# CW32L031 register map
Vendor: Wuhan Xinyuan Semiconductor Co.,Ltd; Series: CW32L03xx; File version: 1.2
CPU: CM0+ r0p1, little endian, no MPU, no FPU, 3 interrupt priority bits
Registers are 32-bit, read-write, no defined reset value unless marked. A register's access mark holds for its fields unless they carry their own. Offsets are from the block's base; [hi:lo] are bit positions; {n}, {i} and the like mark numbered series; 'fields as' and 'values as' point back to an identical list.

## ATIM
Base 0x40012C00
0x00 ARR
  [15:0] ARR
0x04 CNT
  [15:0] CNT
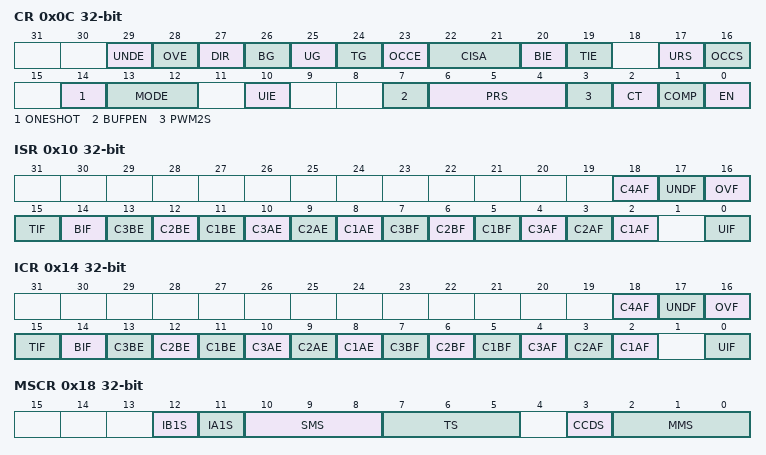
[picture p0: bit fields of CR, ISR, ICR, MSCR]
0x0C CR
  [29] UNDE
  [28] OVE
  [27] DIR
  [26] BG
  [25] UG
  [24] TG
  [23] OCCE
  [22:21] CISA
  [20] BIE
  [19] TIE
  [17] URS
  [16] OCCS
  [14] ONESHOT
  [13:12] MODE — Please keep 10/11
  [10] UIE
  [7] BUFPEN
  [6:4] PRS
  [3] PWM2S
  [2] CT
  [1] COMP
  [0] EN
0x10 ISR ro
  [18] C4AF, [17] UNDF, [16] OVF, [15] TIF, [14] BIF, [13] C3BE, [12] C2BE, [11] C1BE, [10] C3AE, [9] C2AE, [8] C1AE, [7] C3BF, [6] C2BF, [5] C1BF, [4] C3AF, [3] C2AF, [2] C1AF, [0] UIF
0x14 ICR
  fields as ISR
0x18 MSCR
  [12] IB1S, [11] IA1S, [10:8] SMS, [7:5] TS, [3] CCDS, [2:0] MMS
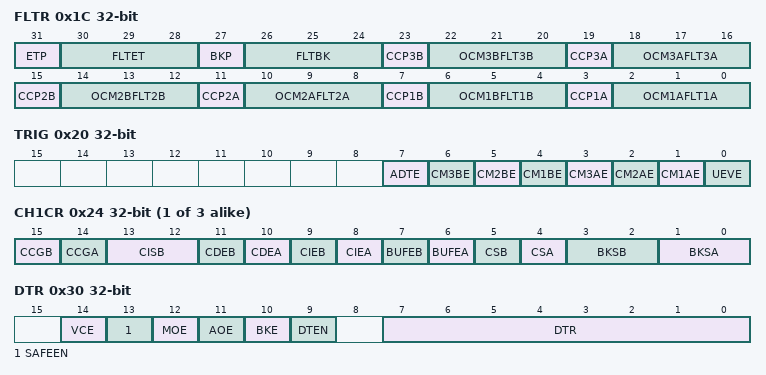
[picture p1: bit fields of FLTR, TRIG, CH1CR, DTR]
0x1C FLTR
  [31] ETP, [30:28] FLTET, [27] BKP, [26:24] FLTBK, [23] CCP3B, [22:20] OCM3BFLT3B, [19] CCP3A, [18:16] OCM3AFLT3A, [15] CCP2B, [14:12] OCM2BFLT2B, [11] CCP2A, [10:8] OCM2AFLT2A, [7] CCP1B, [6:4] OCM1BFLT1B, [3] CCP1A, [2:0] OCM1AFLT1A
0x20 TRIG
  [7] ADTE, [6] CM3BE, [5] CM2BE, [4] CM1BE, [3] CM3AE, [2] CM2AE, [1] CM1AE, [0] UEVE
{0x20+4i} CH{i}CR (i=1..3)
  [15] CCGB, [14] CCGA, [13:12] CISB, [11] CDEB, [10] CDEA, [9] CIEB, [8] CIEA, [7] BUFEB, [6] BUFEA, [5] CSB, [4] CSA, [3:2] BKSB, [1:0] BKSA
0x30 DTR
  [14] VCE, [13] SAFEEN, [12] MOE, [11] AOE, [10] BKE, [9] DTEN, [7:0] DTR
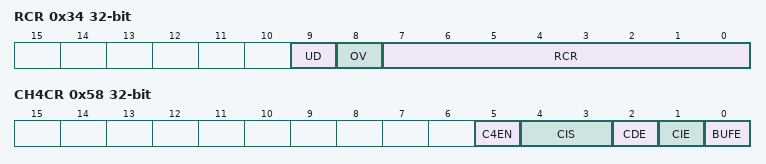
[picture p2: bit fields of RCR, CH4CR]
0x34 RCR
  [9] UD, [8] OV, [7:0] RCR
{0x34+8i} CH{i}CCRA (i=1..3)
  [15:0] CCR{i}A
{0x38+8i} CH{i}CCRB (i=1..3)
  [15:0] CCR{i}B
0x54 CH4CCR
  [15:0] CCR4
0x58 CH4CR
  [5] C4EN, [4:3] CIS, [2] CDE, [1] CIE, [0] BUFE

## AWT
Base 0x40014C00
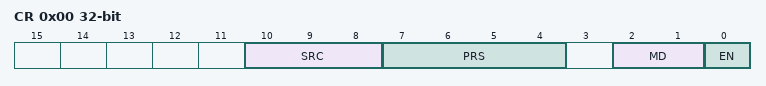
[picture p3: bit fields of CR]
0x00 CR — Control register
  [10:8] SRC, [7:4] PRS, [2:1] MD, [0] EN
0x04 ARR — Auto reload register
  [15:0] ARR
0x08 CNT ro — counter
  [15:0] CNT
0x10 IER — Interrupt enable register
  [3] UD
0x14 ISR ro — Interrupt status register
  [3] UD
0x1C ICR — Interrupt flag clear register
  [3] UD

## BTIM1 — Base Timer 1
Base 0x40014800
Same registers: BTIM2 0x40014900, BTIM3 0x40014A00
0x00 ARR — Auto Reload Register
  [15:0] ARR
0x04 CNT — Counter Register
  [15:0] CNT
0x0C ACR — Advanced Control register
  [6:4] ETRFLT
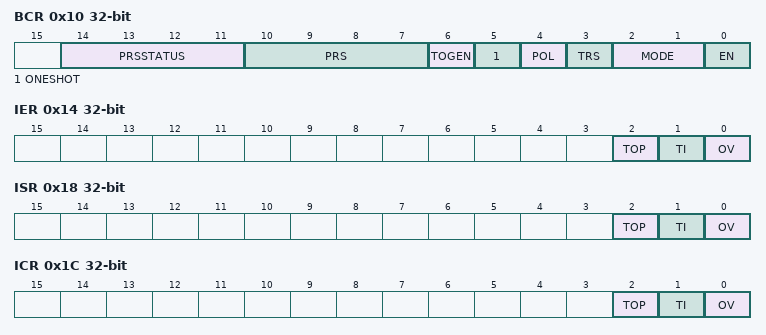
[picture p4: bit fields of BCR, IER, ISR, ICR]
0x10 BCR — Base Control register
  [14:11] PRSSTATUS ro, [10:7] PRS, [6] TOGEN, [5] ONESHOT, [4] POL, [3] TRS, [2:1] MODE, [0] EN
0x14 IER — Interrupt enable register
  [2] TOP, [1] TI, [0] OV
0x18 ISR ro — Interrupt status register
  [2] TOP, [1] TI, [0] OV
0x1C ICR — Interrupt flag clear register
  [2] TOP, [1] TI, [0] OV
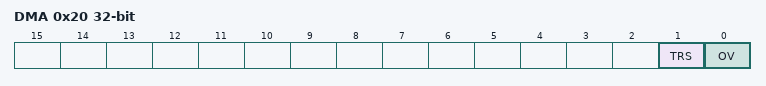
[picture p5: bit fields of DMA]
0x20 DMA — DMA control register
  [1] TRS, [0] OV

## CRC
Base 0x40023000
0x00 CR — Control register
  [3:0] MODE
0x08 DR32 — Data register
0x08 DR16 16-bit (alternate view of DR32) — Data register
0x08 DR8 8-bit (alternate view of DR32) — Data register
0x0C RESULT32 ro — Result register
0x0C RESULT16 16-bit ro (alternate view of RESULT32) — Result register

## DMA
Base 0x40020000
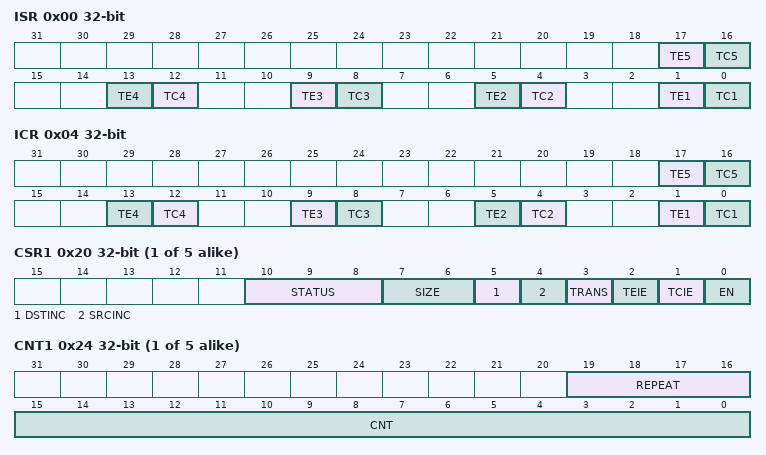
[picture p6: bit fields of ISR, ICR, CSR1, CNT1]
0x00 ISR ro — Interrupt status register
  [4n-3] TE{n} (n=1..5), [4n-4] TC{n} (n=1..5)
0x04 ICR — Interrupt flag clear register
  [4n-3] TE{n} (n=1..5), [4n-4] TC{n} (n=1..5)
{0x0+0x20*i} CSR{i} (i=1..5) — Channel{i} control and status register
  [10:8] STATUS ro, [7:6] SIZE, [5] DSTINC, [4] SRCINC, [3] TRANS, [2] TEIE, [1] TCIE, [0] EN
{0x4+0x20*i} CNT{i} (i=1..5) — Channel{i} counter register
  [19:16] REPEAT, [15:0] CNT
{0x8+0x20*i} SRCADDR{i} (i=1..5) — Channel{i} source address register
  [31:0] SRCADDR
{0xC+0x20*i} DSTADDR{i} (i=1..5) — Channel{i} destination address register
  [31:0] DSTADDR
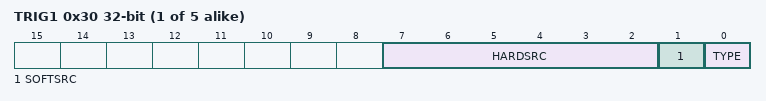
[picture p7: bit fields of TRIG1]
{0x10+0x20*i} TRIG{i} (i=1..5) — Channel{i} trigger register
  [7:2] HARDSRC, [1] SOFTSRC, [0] TYPE

## DMACHANNEL1
Base 0x40020020; alternate view of DMA
Same registers: DMACHANNEL2 0x40020040, DMACHANNEL3 0x40020060, DMACHANNEL4 0x40020080, DMACHANNEL5 0x400200A0
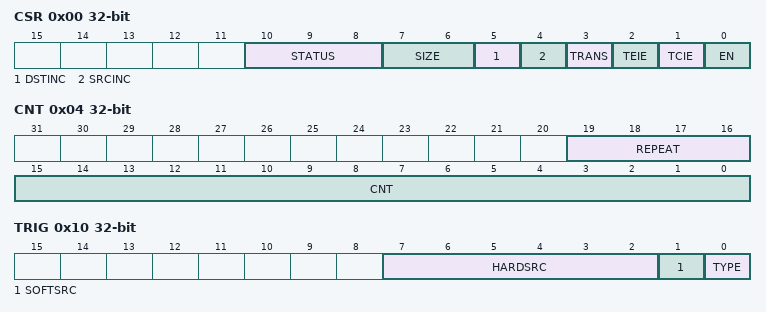
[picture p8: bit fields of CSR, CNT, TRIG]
0x00 CSR — Channel.y control and status register
  [10:8] STATUS ro, [7:6] SIZE, [5] DSTINC, [4] SRCINC, [3] TRANS, [2] TEIE, [1] TCIE, [0] EN
0x04 CNT — Channel.y counter register
  [19:16] REPEAT, [15:0] CNT
0x08 SRCADDR — Channel.y source address register
0x0C DSTADDR — Channel.y destination address register
0x10 TRIG — Channel.y trigger register
  [7:2] HARDSRC, [1] SOFTSRC, [0] TYPE
